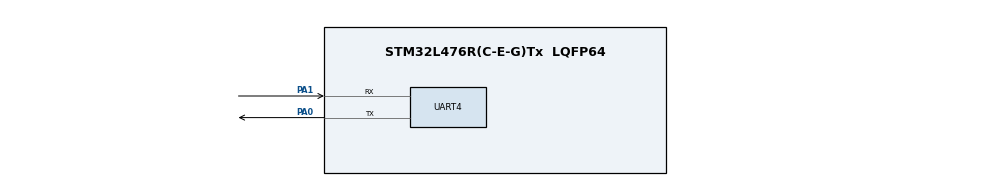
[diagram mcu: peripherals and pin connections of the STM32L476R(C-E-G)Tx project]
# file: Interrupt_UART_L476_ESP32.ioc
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Mcu.Family=STM32L4
Mcu.Name=STM32L476R(C-E-G)Tx
Mcu.Package=LQFP64
NVIC.PriorityGroup=NVIC_PRIORITYGROUP_4
NVIC.UART4_IRQn=true\:0\:0\:false\:false\:true\:true\:true\:true
PA0.Mode=Asynchronous
PA0.Signal=UART4_TX
PA1.Mode=Asynchronous
PA1.Signal=UART4_RX
ProjectManager.HeapSize=0x200
ProjectManager.StackSize=0x400
ProjectManager.TargetToolchain=MDK-ARM V5.32
RCC.HSE_VALUE=8000000
RCC.HSI_VALUE=16000000
RCC.LSE_VALUE=32768
RCC.MSI_VALUE=4000000
RCC.VCOOutputFreq_Value=32000000
TIM2.Period=9
TIM2.Prescaler=3
UART4.DMADisableonRxErrorParam=UART_ADVFEATURE_DMA_DISABLEONRXERROR
VP_TIM2_VS_ClockSourceINT.Mode=Internal
board=custom

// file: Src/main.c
/* USER CODE BEGIN Header */
/**
  ******************************************************************************
  * @file           : main.c
  * @brief          : Main program body
  ******************************************************************************
  * @attention
  *
  * Copyright (c) 2024 STMicroelectronics.
  * All rights reserved.
  *
  * This software is licensed under terms that can be found in the LICENSE file
  * in the root directory of this software component.
  * If no LICENSE file comes with this software, it is provided AS-IS.
  *
  ******************************************************************************
  */
/* USER CODE END Header */
#include "main.h"

/* USER CODE BEGIN Includes */
#include "string.h"
/* USER CODE END Includes */

/* USER CODE BEGIN PV */
char *str = "GotIt\n";
char receivedStr[15];
/* USER CODE END PV */

void SystemClock_Config(void);
static void MX_GPIO_Init(void);
static void MX_TIM2_Init(void);
static void MX_UART4_Init(void);
/* USER CODE BEGIN PFP */
void UART_SendChar(uint8_t ch);
uint8_t UART_ReceiveChar(void);
void UART_SendString(char *str);
void UART_ReceiveString(char *buffer, uint8_t maxLength);
/* USER CODE END PFP */

int main(void)
{

  /* MCU Configuration--------------------------------------------------------*/

  /* Reset of all peripherals, Initializes the Flash interface and the Systick. */
  LL_APB2_GRP1_EnableClock(LL_APB2_GRP1_PERIPH_SYSCFG);
  LL_APB1_GRP1_EnableClock(LL_APB1_GRP1_PERIPH_PWR);

  /* System interrupt init*/
  NVIC_SetPriorityGrouping(NVIC_PRIORITYGROUP_4);

  /* SysTick_IRQn interrupt configuration */
  NVIC_SetPriority(SysTick_IRQn, NVIC_EncodePriority(NVIC_GetPriorityGrouping(),15, 0));

  /* Configure the system clock */
  SystemClock_Config();

  /* Initialize all configured peripherals */
  MX_GPIO_Init();
  MX_TIM2_Init();
  MX_UART4_Init();

  /* Infinite loop */
  while (1)
  {
		memset(receivedStr, 0, sizeof(receivedStr));
  }
}

void SystemClock_Config(void)
{
  LL_FLASH_SetLatency(LL_FLASH_LATENCY_0);
  while(LL_FLASH_GetLatency()!= LL_FLASH_LATENCY_0)
  {
  }
  LL_PWR_SetRegulVoltageScaling(LL_PWR_REGU_VOLTAGE_SCALE1);
  while (LL_PWR_IsActiveFlag_VOS() != 0)
  {
  }
  LL_RCC_MSI_Enable();

   /* Wait till MSI is ready */
  while(LL_RCC_MSI_IsReady() != 1)
  {

  }
  LL_RCC_MSI_EnableRangeSelection();
  LL_RCC_MSI_SetRange(LL_RCC_MSIRANGE_6);
  LL_RCC_MSI_SetCalibTrimming(0);
  LL_RCC_SetSysClkSource(LL_RCC_SYS_CLKSOURCE_MSI);

   /* Wait till System clock is ready */
  while(LL_RCC_GetSysClkSource() != LL_RCC_SYS_CLKSOURCE_STATUS_MSI)
  {

  }
  LL_RCC_SetAHBPrescaler(LL_RCC_SYSCLK_DIV_1);
  LL_RCC_SetAPB1Prescaler(LL_RCC_APB1_DIV_1);
  LL_RCC_SetAPB2Prescaler(LL_RCC_APB2_DIV_1);

  LL_Init1msTick(4000000);

  LL_SetSystemCoreClock(4000000);
}

static void MX_TIM2_Init(void)
{

  LL_TIM_InitTypeDef TIM_InitStruct = {0};

  /* Peripheral clock enable */
  LL_APB1_GRP1_EnableClock(LL_APB1_GRP1_PERIPH_TIM2);

  TIM_InitStruct.Prescaler = 4000-1;
  TIM_InitStruct.CounterMode = LL_TIM_COUNTERMODE_UP;
  TIM_InitStruct.Autoreload = 0xFFFF-1;
  TIM_InitStruct.ClockDivision = LL_TIM_CLOCKDIVISION_DIV1;
  LL_TIM_Init(TIM2, &TIM_InitStruct);
  LL_TIM_DisableARRPreload(TIM2);
  LL_TIM_SetClockSource(TIM2, LL_TIM_CLOCKSOURCE_INTERNAL);
  LL_TIM_SetTriggerOutput(TIM2, LL_TIM_TRGO_RESET);
  LL_TIM_DisableMasterSlaveMode(TIM2);
  /* USER CODE BEGIN TIM2_Init 2 */
	LL_TIM_EnableCounter(TIM2);
  /* USER CODE END TIM2_Init 2 */

}

static void MX_UART4_Init(void)
{

  LL_USART_InitTypeDef UART_InitStruct = {0};

  LL_GPIO_InitTypeDef GPIO_InitStruct = {0};

  LL_RCC_SetUARTClockSource(LL_RCC_UART4_CLKSOURCE_PCLK1);

  /* Peripheral clock enable */
  LL_APB1_GRP1_EnableClock(LL_APB1_GRP1_PERIPH_UART4);

  LL_AHB2_GRP1_EnableClock(LL_AHB2_GRP1_PERIPH_GPIOA);
  /**UART4 GPIO Configuration
  PA0   ------> UART4_TX
  PA1   ------> UART4_RX
  */
  GPIO_InitStruct.Pin = LL_GPIO_PIN_0|LL_GPIO_PIN_1;
  GPIO_InitStruct.Mode = LL_GPIO_MODE_ALTERNATE;
  GPIO_InitStruct.Speed = LL_GPIO_SPEED_FREQ_VERY_HIGH;
  GPIO_InitStruct.OutputType = LL_GPIO_OUTPUT_PUSHPULL;
  GPIO_InitStruct.Pull = LL_GPIO_PULL_NO;
  GPIO_InitStruct.Alternate = LL_GPIO_AF_8;
  LL_GPIO_Init(GPIOA, &GPIO_InitStruct);

  /* UART4 interrupt Init */
  NVIC_SetPriority(UART4_IRQn, NVIC_EncodePriority(NVIC_GetPriorityGrouping(),0, 0));
  NVIC_EnableIRQ(UART4_IRQn);

  UART_InitStruct.BaudRate = 115200;
  UART_InitStruct.DataWidth = LL_USART_DATAWIDTH_8B;
  UART_InitStruct.StopBits = LL_USART_STOPBITS_1;
  UART_InitStruct.Parity = LL_USART_PARITY_NONE;
  UART_InitStruct.TransferDirection = LL_USART_DIRECTION_TX_RX;
  UART_InitStruct.HardwareFlowControl = LL_USART_HWCONTROL_NONE;
  UART_InitStruct.OverSampling = LL_USART_OVERSAMPLING_16;
  LL_USART_Init(UART4, &UART_InitStruct);
  LL_USART_DisableDMADeactOnRxErr(UART4);
  LL_USART_ConfigAsyncMode(UART4);
  LL_USART_Enable(UART4);
  /* USER CODE BEGIN UART4_Init 2 */
	/* Polling USART initialisation */
  while((!(LL_USART_IsActiveFlag_TEACK(UART4))) || (!(LL_USART_IsActiveFlag_REACK(UART4))))
  {
  }
	LL_USART_EnableIT_RXNE(UART4);
  /* USER CODE END UART4_Init 2 */

}

static void MX_GPIO_Init(void)
{

  /* GPIO Ports Clock Enable */
  LL_AHB2_GRP1_EnableClock(LL_AHB2_GRP1_PERIPH_GPIOA);

}

/* USER CODE BEGIN 4 */
void delay_ms(uint32_t timeDelay)
{
    LL_TIM_SetCounter(TIM2, 0);

    while (LL_TIM_GetCounter(TIM2) < timeDelay);
}

void UART_SendChar(uint8_t ch)
{
    while (!LL_USART_IsActiveFlag_TXE(UART4));
    LL_USART_TransmitData8(UART4, ch);
    while (!LL_USART_IsActiveFlag_TC(UART4));
}

uint8_t UART_ReceiveChar(void)
{
    while (!LL_USART_IsActiveFlag_RXNE(UART4));
    return LL_USART_ReceiveData8(UART4);
}

void UART_SendString(char *str)
{
    while (*str)
		{
        UART_SendChar(*str++);
    }
}

void UART_ReceiveString(char *buffer, uint8_t maxLength)
{
    uint8_t index = 0;
    char receivedChar;

    do {
        receivedChar = UART_ReceiveChar();
        buffer[index++] = receivedChar;
    } while (receivedChar != '\n' && index < maxLength - 1);

    buffer[index] = '\0';
}

/**
  * @brief This function handles UART4 global interrupt.
  */
void UART4_IRQHandler(void)
{
	if(LL_USART_IsEnabledIT_RXNE(UART4))
  {
    UART_ReceiveString(receivedStr, 15);
		UART_SendString(str);
  }
}
/* USER CODE END 4 */

void Error_Handler(void)
{
  __disable_irq();
  while (1)
  {
  }
}
